# regs-internal register map
Registers are 32-bit, access not given, no defined reset value unless marked. A register's access mark holds for its fields unless they carry their own. Addresses are absolute; registers are grouped by the start of their names; [hi:lo] are bit positions; {n}, {i} and the like mark numbered series.

## DITHER
0x40001060 DITHER_AMPLITUDE
  [5:0] DITHER_AMP
0x40004018 DITHER_DIS
  [0] DITHER_DIS

## TX
0x40001064 TX_STEP_TIME
  [7:0] TX_STEP_TIME
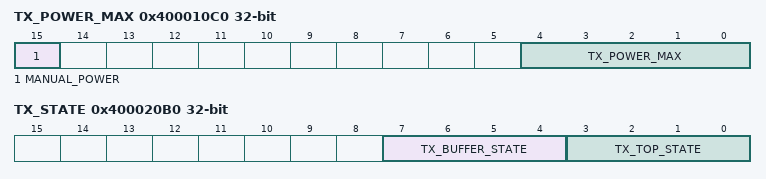
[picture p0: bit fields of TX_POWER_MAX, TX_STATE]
0x400010C0 TX_POWER_MAX
  [15] MANUAL_POWER, [4:0] TX_POWER_MAX
0x40002028 TX_COUNT
  [10:0] TX_COUNT
0x4000206C TX_CRC
  [15:0] TX_CRC
0x400020B0 TX_STATE
  [7:4] TX_BUFFER_STATE, [3:0] TX_TOP_STATE

## GAIN
0x40001068 GAIN_THRESH_MAX
  [7:0] GAIN_THRESH_MAX
0x4000106C GAIN_THRESH_MID
  [7:0] GAIN_THRESH_MID
0x40001070 GAIN_THRESH_MIN
  [7:0] GAIN_THRESH_MIN
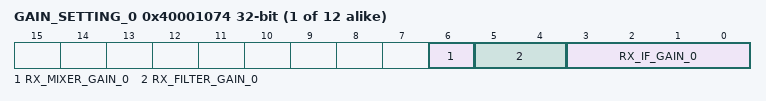
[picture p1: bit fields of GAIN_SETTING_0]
{0x40001074+4i} GAIN_SETTING_{i} (i=0..11)
  [6] RX_MIXER_GAIN_{i}, [5:4] RX_FILTER_GAIN_{i}, [3:0] RX_IF_GAIN_{i}
0x400010A4 GAIN_CTRL_MIN_RF
  [8:0] GAIN_CTRL_MIN_RF
0x400010A8 GAIN_CTRL_MAX_RF
  [8:0] GAIN_CTRL_MAX_RF

## PREAMBLE
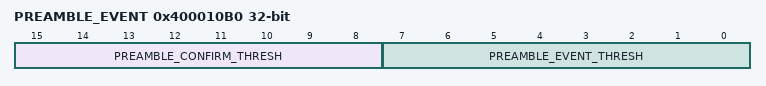
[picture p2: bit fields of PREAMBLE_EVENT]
0x400010B0 PREAMBLE_EVENT
  [15:8] PREAMBLE_CONFIRM_THRESH, [7:0] PREAMBLE_EVENT_THRESH
0x400010B4 PREAMBLE_ABORT_THRESH
  [7:0] PREAMBLE_ABORT_THRESH
0x400010B8 PREAMBLE_ACCEPT_WINDOW
  [6:0] PREAMBLE_ACCEPT_WINDOW

## FREQ
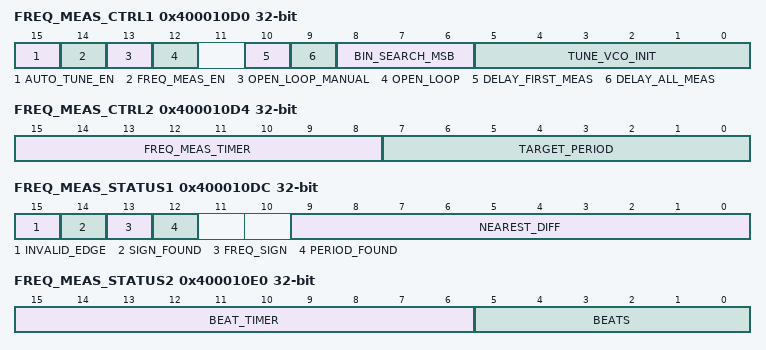
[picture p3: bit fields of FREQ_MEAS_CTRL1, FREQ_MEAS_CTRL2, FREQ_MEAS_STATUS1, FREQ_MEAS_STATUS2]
0x400010D0 FREQ_MEAS_CTRL1
  [15] AUTO_TUNE_EN, [14] FREQ_MEAS_EN, [13] OPEN_LOOP_MANUAL, [12] OPEN_LOOP, [10] DELAY_FIRST_MEAS, [9] DELAY_ALL_MEAS, [8:6] BIN_SEARCH_MSB, [5:0] TUNE_VCO_INIT
0x400010D4 FREQ_MEAS_CTRL2
  [15:8] FREQ_MEAS_TIMER, [7:0] TARGET_PERIOD
0x400010D8 FREQ_MEAS_SHIFT
  [7:0] FREQ_MEAS_SHIFT
0x400010DC FREQ_MEAS_STATUS1
  [15] INVALID_EDGE, [14] SIGN_FOUND, [13] FREQ_SIGN, [12] PERIOD_FOUND, [9:0] NEAREST_DIFF
0x400010E0 FREQ_MEAS_STATUS2
  [15:6] BEAT_TIMER, [5:0] BEATS
0x400010E4 FREQ_MEAS_STATUS3
  [5:0] TUNE_VCO

## SCR
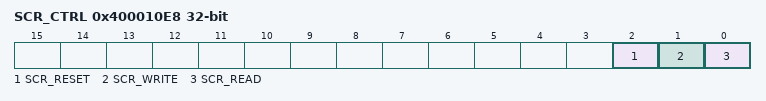
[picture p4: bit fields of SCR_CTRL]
0x400010E8 SCR_CTRL
  [2] SCR_RESET, [1] SCR_WRITE, [0] SCR_READ
0x400010EC SCR_BUSY
  [0] SCR_BUSY
0x400010F0 SCR_ADDR
  [7:0] SCR_ADDR
0x400010F4 SCR_WRITE
  [15:0] SCR_WRITE
0x400010F8 SCR_READ
  [15:0] SCR_READ

## AN
0x40001100 AN_CAL_STATUS
  [3:2] VCO_CTRL
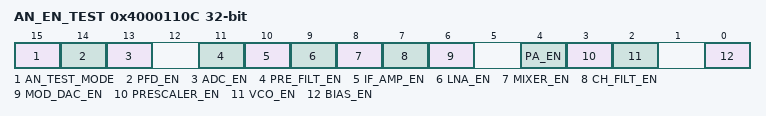
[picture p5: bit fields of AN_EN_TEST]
0x4000110C AN_EN_TEST
  [15] AN_TEST_MODE, [14] PFD_EN, [13] ADC_EN, [11] PRE_FILT_EN, [10] IF_AMP_EN, [9] LNA_EN, [8] MIXER_EN, [7] CH_FILT_EN, [6] MOD_DAC_EN, [4] PA_EN, [3] PRESCALER_EN, [2] VCO_EN, [0] BIAS_EN

## TUNE
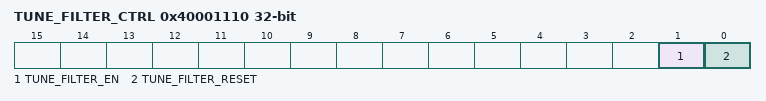
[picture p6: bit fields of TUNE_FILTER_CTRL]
0x40001110 TUNE_FILTER_CTRL
  [1] TUNE_FILTER_EN, [0] TUNE_FILTER_RESET
0x40009020 TUNE_LNA_FILTB
  [0] TUNE_LNA_FILTB

## EXT
{0x40002098+4i} EXT_ADDR_{i} (i=0..3)
  [15:0] EXT_ADDR_{i}

## DMA
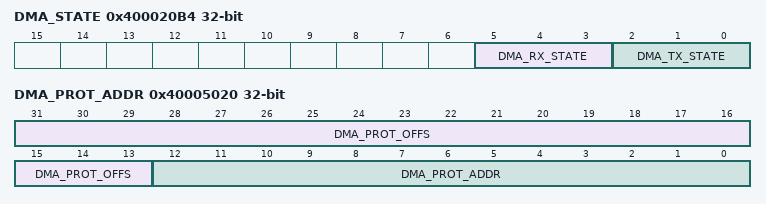
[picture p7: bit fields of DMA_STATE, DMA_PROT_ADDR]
0x400020B4 DMA_STATE
  [5:3] DMA_RX_STATE, [2:0] DMA_TX_STATE
0x40005020 DMA_PROT_ADDR
  [31:13] DMA_PROT_OFFS, [12:0] DMA_PROT_ADDR
0x40005024 DMA_PROT_CH
  [2:0] DMA_PROT_CH

## SECURITY
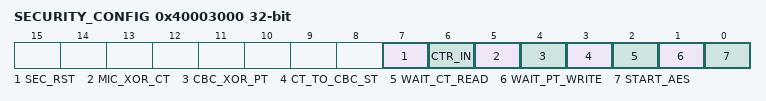
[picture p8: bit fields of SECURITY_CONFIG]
0x40003000 SECURITY_CONFIG
  [7] SEC_RST, [6] CTR_IN, [5] MIC_XOR_CT, [4] CBC_XOR_PT, [3] CT_TO_CBC_ST, [2] WAIT_CT_READ, [1] WAIT_PT_WRITE, [0] START_AES
0x40003004 SECURITY_STATUS
  [0] SEC_BUSY

## CBC
0x40003008 CBC_STATE_0
  [31:0] CBC_STATE
{0x40003008+4i} CBC_STATE_{i} (i=1..3)

## KEY
0x40003038 KEY_0
  [31:0] KEY_O
{0x40003038+4i} KEY_{i} (i=1..3)

## OSC24M
0x40004004 OSC24M_BIASTRIM
  [3:0] OSC24M_BIAS_TRIM
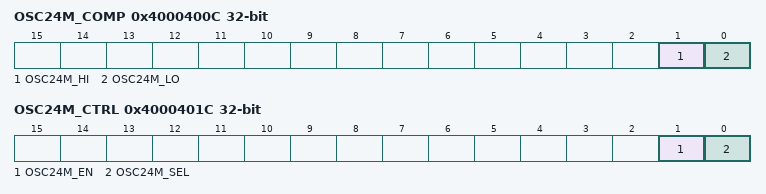
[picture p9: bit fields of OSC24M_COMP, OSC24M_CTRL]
0x4000400C OSC24M_COMP
  [1] OSC24M_HI, [0] OSC24M_LO
0x4000401C OSC24M_CTRL
  [1] OSC24M_EN, [0] OSC24M_SEL

## CLK
0x40004010 CLK_PERIODMODE
  [1:0] CLK_PERIODMODE_FIELD
0x40004014 CLK_PERIOD
  [15:0] CLK_PERIOD_FIELD

## FPEC
0x4000402C FPEC_CLKREQ
  [0] FPEC_CLKREQ_FIELD
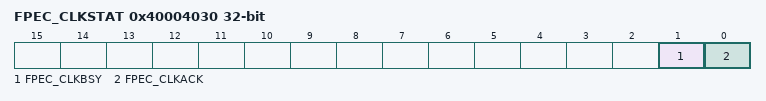
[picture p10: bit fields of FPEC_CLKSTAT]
0x40004030 FPEC_CLKSTAT
  [1] FPEC_CLKBSY, [0] FPEC_CLKACK
0x40008004 FPEC_KEY
  [31:0] FKEYR
